# NANO100BN_v1 register map
File version: 1.0
Registers are 32-bit, read-write, reset 0x0 unless marked. A register's access mark holds for its fields unless they carry their own. Offsets are from the block's base; [hi:lo] are bit positions; {n}, {i} and the like mark numbered series; 'fields as' and 'values as' point back to an identical list.

## PWM0 — PWM Register Map
Base 0x40040000
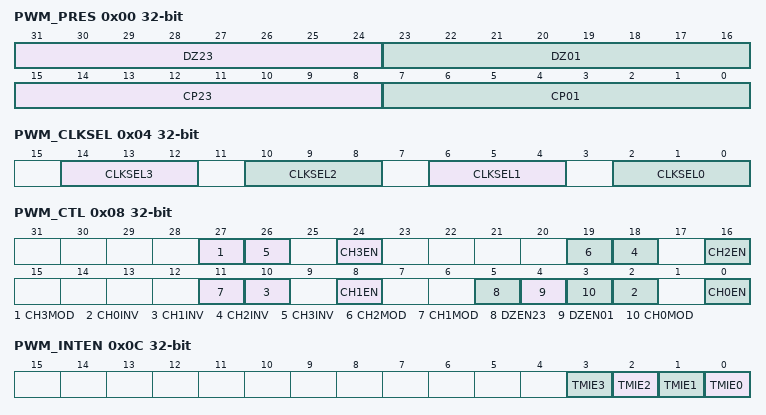
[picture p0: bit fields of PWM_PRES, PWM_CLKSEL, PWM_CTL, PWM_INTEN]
0x00 PWM_PRES — PWM Prescaler Register
  [31:24] DZ23 — Dead Zone Interval Register for CH2 and CH3 Pair. These 8 bits determine dead zone length. The unit time of dead zone length is received from clock selector 2.
  [23:16] DZ01 — Dead Zone Interval Register for CH0 and CH1 Pair. These 8 bits determine dead zone length. The unit time of dead zone length is received from clock selector 0.
  [15:8] CP23 — Clock Prescaler 2 for PWM Timer 2 3. Clock input is divided by (CP23 + 1) before it is fed to the counter 2 3
  [7:0] CP01 — Clock Prescaler 0 for PWM Timer 0 1. Clock input is divided by (CP01 + 1) before it is fed to the counter 0 1
0x04 PWM_CLKSEL — PWM Clock Select Register
  [14:12] CLKSEL3 — Timer 3 Clock Source Selection
  [10:8] CLKSEL2 — Timer 2Clock Source Selection. Select clock input for timer 2. (Table is the same as CLKSEL3)
  [6:4] CLKSEL1 — Timer 1 Clock Source Selection. Select clock input for timer 1. (Table is the same as CLKSEL3)
  [2:0] CLKSEL0 — Timer 0 Clock Source Selection. Select clock input for timer 0. (Table is the same as CLKSEL3)
0x08 PWM_CTL — PWM Control Register
  [27] CH3MOD — PWM-Timer 3 Continuous/One-shot Mode. Note: If there is a rising transition at this bit, it will cause CN and CM of PWM0_DUTY3 to be cleared.
    0=One-Shot Mode; 1=Continuous Mode
  [8n+2] CH{n}INV (n=0..3) — PWM-Timer {n} Output Inverter ON/OFF
    0=Inverter OFF; 1=Inverter ON
  [8n] CH{n}EN (n=0..3) — PWM-Timer {n} Enable/Disable Start Run
    0=PWM-Timer {n} Running Stopped; 1=PWM-Timer {n} Start Run Enabled
  [19] CH2MOD — PWM-Timer 2 Continuous/One-shot Mode. Note: If there is a rising transition at this bit, it will cause CN and CM of PWM0_DUTY2 be cleared.
    0=One-Shot Mode; 1=Continuous Mode
  [11] CH1MOD — PWM-Timer 1 Continuous/One-shot Mode. Note: If there is a rising transition at this bit, it will cause CN and CM of PWM0_DUTY1 to be cleared.
    0=One-Shot Mode; 1=Continuous Mode
  [5] DZEN23 — Dead-Zone 2 Generator Enable/Disable. Note: When Dead-Zone Generator is enabled, the pair of PWM2 and PWM3 becomes a complementary pair.
    0=Disabled; 1=Enabled
  [4] DZEN01 — Dead-Zone 0 Generator Enable/Disable. Note: When Dead-Zone Generator is enabled, the pair of PWM0 and PWM1 becomes a complementary pair.
    0=Disabled; 1=Enabled
  [3] CH0MOD — PWM-Timer 0 Continuous/One-Shot Mode. Note: If there is a rising transition at this bit, it will cause CN and CM of PWM0_DUTY0 to be cleared.
    0=One-Shot Mode; 1=Continuous Mode
0x0C PWM_INTEN — PWM Interrupt Enable Register
  [all] fields
    0=Disabled; 1=Enabled
  [n] TMIE{n} (n=0..3) — PWM Timer {n} Interrupt Enable
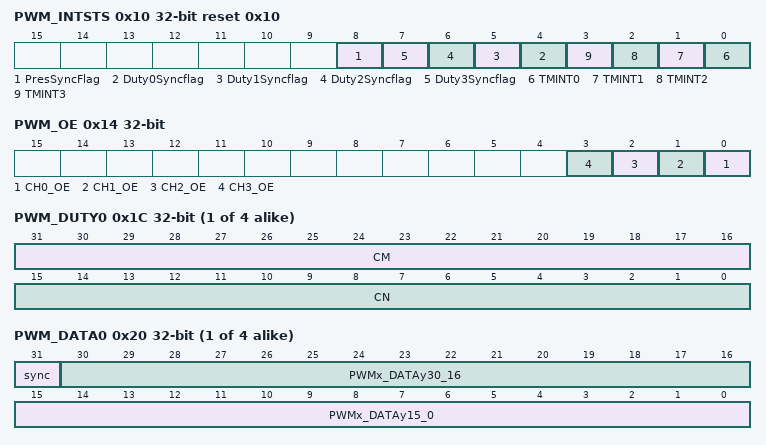
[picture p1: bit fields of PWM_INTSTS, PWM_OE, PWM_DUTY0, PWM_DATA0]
0x10 PWM_INTSTS reset 0x10 — PWM Interrupt Indication Register
  [8] PresSyncFlag — Prescale Synchronize Flag. Note: software should check this flag when writing Prescale, if this flag is set, and user ignore this flag and change Prescale, the Prescale may be wrong for one prescale cycle
    0=Prescale has been synchronized to ECLK domain; 1=Prescale is synchronizing to ECLK domain
  [n+4] Duty{n}Syncflag (n=0..3) — Duty{n} Synchronize Flag. Note: software should check this flag when writing duty{n}, if this flag is set, and user ignore this flag and change duty{n}, the corresponding CNR and CMR may be wrong for one duty cycle
    0=Duty{n} has been synchronized to ECLK domain; 1=Duty{n} is synchronizing to ECLK domain
  [n] TMINT{n} (n=0..3) — PWM Timer {n} Interrupt Flag. Flag is set by hardware when PWM{n} down counter reaches zero, software can clear this bit by writing a one to it.
0x14 PWM_OE — PWM Output Enable for PWM0~PWM3
  [n] CH{n}_OE (n=0..3) — PWM CH{n} Output Enable Register. Note: The corresponding GPI/O pin also must be switched to PWM function (refer to GPx_MFP)
    0=PWM CH{n} output to pin Disabled; 1=PWM CH{n} output to pin Enabled
{0x1C+0xC*i} PWM_DUTY{i} (i=0..3) — PWM Counter/Comparator Register {i}
  [31:16] CM — PWM Comparator Register. CM determines the PWM duty. Note: Any write to CM will take effect in next PWM cycle.
  [15:0] CN — PWM Counter/Timer Loaded Value. CN determines the PWM period. Note: Any write to CN will take effect in next PWM cycle.
{0x20+0xC*i} PWM_DATA{i} ro (i=0..3) — PWM Data Register {i}
  [31] sync — Indicate that CNR value is sync to PWM counter. Note: when the corresponding cascade enable .bit is set is bit will not appear in the corresponding channel
    0=CNR value is sync to PWM counter; 1=CNR value is not sync to PWM counter
  [30:16] PWMx_DATAy30_16 — PWM Data Register. User can monitor PWMx_DATAy to know the current value in 32-bit down count counter. Notes:This will be valid only for the corresponding cascade enable .bit is set
  [15:0] PWMx_DATAy15_0 — PWM Data Register. User can monitor PWMx_DATAy to know the current value in 16-bit down count counter.
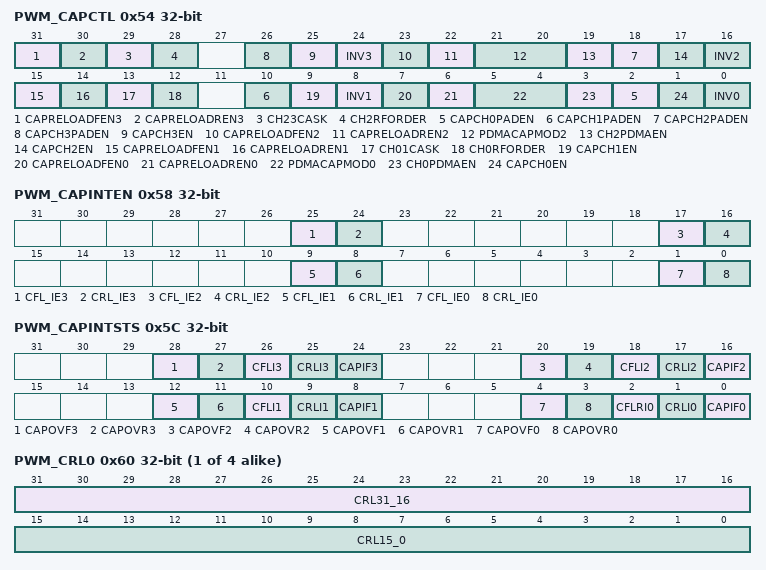
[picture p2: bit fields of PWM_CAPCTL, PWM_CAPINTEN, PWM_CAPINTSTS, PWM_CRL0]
0x54 PWM_CAPCTL — Capture Control Register
  [31] CAPRELOADFEN3 — Reload CNR3 when CH3 falling capture Event Comes
    0=Falling capture reload for CH3 Disabled; 1=Falling capture reload for CH3 Enabled
  [30] CAPRELOADREN3 — Reload CNR3 when CH3 Rising Capture Event Comes
    0=Rising capture reload for CH3 Disabled; 1=Rising capture reload for CH3 Enabled
  [29] CH23CASK — Cascade channel 2 and channel 3 PWM counter for capturing usage
  [28] CH2RFORDER
    0=PWM_CFL2 is the first captured data to memory; 1=PWM_CRL2 is the first captured data to memory
  [8n+2] CAPCH{n}PADEN (n=0..3) — Capture Input Enable Register
    0=OFF; 1=ON
  [25] CAPCH3EN — Capture Channel 3 transition Enable/Disable. When Enabled, Capture latched the PMW-timer and saved to PWM_CRL3 (Rising latch) and PWM_CFL3 (Falling latch). When Disabled, Capture does not update PWM_CRL3 and PWM_CFL3, and disable Channel 3 Interrupt.
    0=Capture function on channel 3 Disabled; 1=Capture function on channel 3 Enabled
  [8n] INV{n} (n=0..3) — Channel {n} Inverter ON/OFF
    0=Inverter OFF; 1=Inverter ON. Reverse the input signal from GPIO before fed to Capture timer
  [23] CAPRELOADFEN2 — Reload CNR2 when CH2 capture failing event coming
    0=Failing capture reload for CH2 Disabled; 1=Failing capture reload for CH2 Enabled
  [22] CAPRELOADREN2 — Reload CNR2 when CH2 capture rising event coming
    0=Rising capture reload for CH2 Disabled; 1=Rising capture reload for CH2 Enabled
  [21:20] PDMACAPMOD2 — Select CRL2 or CFL2 for PDMA Transfer
  [19] CH2PDMAEN — Channel 2 PDMA Enable
    0=Channel 2 PDMA function Disabled; 1=Channel 2 PDMA function Enabled for the channel 2 captured data and transfer to memory
  [17] CAPCH2EN — Capture Channel 2 transition Enable/Disable. When Enabled, Capture latched the PWM-timer value and saved to PWM_CRL2 (Rising latch) and PWM_CFL2 (Falling latch). When Disabled, Capture does not update PWM_CRL2 and PWM_CFL2, and disable Channel 2 Interrupt.
    0=Capture function on channel 2 Disabled; 1=Capture function on channel 2 Enabled
  [15] CAPRELOADFEN1 — Reload CNR1 when CH1 capture falling event coming
    0=Capture falling reload for CH1 Disabled; 1=Capture falling reload for CH1 Enabled
  [14] CAPRELOADREN1 — Reload CNR1 when CH1 Capture Rising Event Comes
    0=Rising capture reload for CH1 Disabled; 1=Rising capture reload for CH1 Enabled
  [13] CH01CASK — Cascade channel 0 and channel 1 PWM timer for capturing usage
  [12] CH0RFORDER
    0=PWM_CFL0 is the first captured data to memory; 1=PWM_CRL0 is the first captured data to memory
  [9] CAPCH1EN — Capture Channel 1 transition Enable/Disable. When Enabled, Capture latched the PMW-counter and saved to PWM_CRL1 (Rising latch) and PWM_CFL1 (Falling latch). When Disabled, Capture does not update PWM_CRL1 and PWM_CFL1, and disable Channel 1 Interrupt.
    0=Capture function on channel 1 Disabled; 1=Capture function on channel 1 Enabled
  [7] CAPRELOADFEN0 — Reload CNR0 when CH0 Capture Falling Event Comes
    0=Falling capture reload for CH0 Disabled; 1=Falling capture reload for CH0 Enabled
  [6] CAPRELOADREN0 — Reload CNR0 when CH0 Capture Rising Event Comes
    0=Rising capture reload for CH0 Disabled; 1=Rising capture reload for CH0 Enabled
  [5:4] PDMACAPMOD0 — Select CRL0 or CFL0 for PDMA Transfer
  [3] CH0PDMAEN — Channel 0 PDMA Enable
    0=Channel 0 PDMA function Disabled; 1=Channel 0 PDMA function Enabled for the channel 0 captured data and transfer to memory
  [1] CAPCH0EN — Capture Channel 0 transition Enable/Disable. When Enabled, Capture latched the PWM-timer value and saved to PWM_CRL0 (Rising latch) and PWM_CFL0 (Falling latch). When Disabled, Capture does not update PWM_CRL0 and PWM_CFL0, and disable Channel 0 Interrupt.
    0=Capture function on channel 0 Disabled; 1=Capture function on channel 0 Enabled
0x58 PWM_CAPINTEN — Capture interrupt enable Register
  [25] CFL_IE3 — Channel 3 Falling Latch Interrupt Enable ON/OFF. When Enabled, if Capture detects Channel 3 has falling transition, Capture issues an Interrupt.
    0=Falling latch interrupt Disabled; 1=Falling latch interrupt Enabled
  [24] CRL_IE3 — Channel 3 Rising Latch Interrupt Enable ON/OFF. When Enabled, if Capture detects Channel 3 has rising transition, Capture issues an Interrupt.
    0=Rising latch interrupt Disabled; 1=Rising latch interrupt Enabled
  [17] CFL_IE2 — Channel 2 Falling Latch Interrupt Enable ON/OFF. When Enabled, if Capture detects Channel 2 has falling transition, Capture issues an Interrupt.
    values as CFL_IE3
  [16] CRL_IE2 — Channel 2 Rising Latch Interrupt Enable ON/OFF. When Enabled, if Capture detects Channel 2 has rising transition, Capture issues an Interrupt.
    values as CRL_IE3
  [9] CFL_IE1 — Channel 1 Falling Latch Interrupt Enable. When Enabled, if Capture detects Channel 1 has falling transition, Capture issues an Interrupt.
    values as CFL_IE3
  [8] CRL_IE1 — Channel 1 Rising Latch Interrupt Enable. When Enabled, if Capture detects Channel 1 has rising transition, Capture issues an Interrupt.
    values as CRL_IE3
  [1] CFL_IE0 — Channel 0 Falling Latch Interrupt Enable ON/OFF. When Enabled, if Capture detects Channel 0 has falling transition, Capture issues an Interrupt.
    values as CFL_IE3
  [0] CRL_IE0 — Channel 0 Rising Latch Interrupt Enable ON/OFF. When Enabled, if Capture detects Channel 0 has rising transition, Capture issues an Interrupt.
    values as CRL_IE3
0x5C PWM_CAPINTSTS — Capture Interrupt Indication Register
  [28] CAPOVF3 — Capture Falling Flag Over Run for Channel 3. This flag indicate CFL3 update faster than software reading it when it is set. This bit will be cleared automatically when user clear CFLI3 bit 26 of PWM_CAPINTSTS
  [27] CAPOVR3 — Capture Rising Flag Over Run for Channel 3. This flag indicate CRL3update faster than software reading it when it is set. This bit will be cleared automatically when user clear CRLI3 bit 25 of PWM_CAPINTSTS
  [26] CFLI3 — PWM_CFL3 Latched Indicator Bit. When input channel 3 has a falling transition, PWM_CFL3 was latched with the value of PWM down-counter and this bit is set by hardware, software can clear this bit by writing 1 to it.
  [25] CRLI3 — PWM_CRL3 Latched Indicator Bit. When input channel 3 has a rising transition, PWM_CRL3 was latched with the value of PWM down-counter and this bit is set by hardware, software can clear this bit by writing 1 to it.
  [8n] CAPIF{n} (n=0..3) — Capture{n} Interrupt Indication Flag
  [20] CAPOVF2 — Capture Falling Flag Over Run for Channel 2. This flag indicate CFL2 update faster than software reading it when it is set. This bit will be cleared automatically when user clear CFLI2 bit 18 of PWM_CAPINTSTS
  [19] CAPOVR2 — Capture Rising Flag Over Run for Channel 2. This flag indicate CRL2 update faster than software reading it when it is set. This bit will be cleared automatically when user clear CRLI2 bit 17 of PWM_CAPINTSTS
  [18] CFLI2 — PWM_CFL2 Latched Indicator Bit. When input channel 2 has a falling transition, PWM0_CFL2 was latched with the value of PWM down-counter and this bit is set by hardware, software can clear this bit by writing 1 to it.
  [17] CRLI2 — PWM_CRL2 Latched Indicator Bit. When input channel 2 has a rising transition, PWM0_CRL2 was latched with the value of PWM down-counter and this bit is set by hardware, software can clear this bit by writing 1 to it.
  [12] CAPOVF1 — Capture Falling Flag Over Run for Channel 1. This flag indicate CFL1 update faster than software reading it when it is set. This bit will be cleared automatically when user clear CFLI1 bit 10 of PWM_CAPINTSTS
  [11] CAPOVR1 — Capture Rising Flag Over Run for Channel 1. This flag indicate CRL1 update faster than software reading it when it is set. This bit will be cleared automatically when user clear CRLI1 bit 9 of PWM_CAPINTSTS
  [10] CFLI1 — PWM_CFL1 Latched Indicator Bit. When input channel 1 has a falling transition, PWM0_CFL1 was latched with the value of PWM down-counter and this bit is set by hardware, software can clear this bit by writing 1 to it.
  [9] CRLI1 — PWM_CRL1 Latched Indicator Bit. When input channel 1 has a rising transition, PWM0_CRL1 was latched with the value of PWM down-counter and this bit is set by hardware, software can clear this bit by writing 1 to it.
  [4] CAPOVF0 — Capture Falling Flag Over Run for Channel 0. This flag indicate CFL0 update faster than software reading it when it is set.
  [3] CAPOVR0 — Capture Rising Flag Over Run for Channel 0. This flag indicate CRL0 update faster than software reading it when it is set. This bit will be cleared automatically when user clears CRLI0 bit 1 of PWM_CAPINTSTS.
  [2] CFLRI0 — PWM_CFL0 Latched Indicator Bit. When input channel 0 has a falling transition, PWM0_CFL0 was latched with the value of PWM down-counter and this bit is set by hardware, software can clear this bit by writing 1 to it.
  [1] CRLI0 — PWM_CRL0 Latched Indicator Bit. When input channel 0 has a rising transition, PWM0_CRL0 was latched with the value of PWM down-counter and this bit is set by hardware, software can clear this bit by writing 1 to it.
{0x60+8i} PWM_CRL{i} ro (i=0..3) — Capture Rising Latch Register (Channel {i})
  [31:16] CRL31_16 — Upper Half Word of 32-bit Capture Data when Cascade Enabled. When cascade is enabled for capture channel 0, 2,the original 16 bit counter extend to 32 bit, and capture result CRL0 and CRL2 are also extend to 32 bit,
  [15:0] CRL15_0 — Capture Rising Latch Register. Latch the PWM counter when Channel 0/1/2/3 has rising transition.
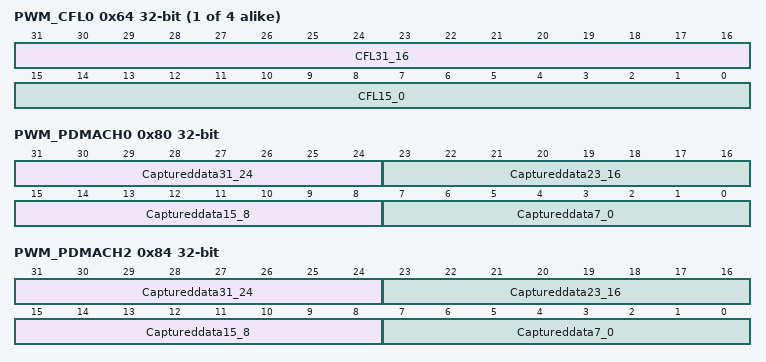
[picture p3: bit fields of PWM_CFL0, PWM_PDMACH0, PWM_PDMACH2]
{0x64+8i} PWM_CFL{i} ro (i=0..3) — Capture Falling Latch Register (Channel {i})
  [31:16] CFL31_16 — Upper Half Word of 32-bit Capture Data When Cascade Enabled. When cascade is enabled for capture channel 0, 2, the original 16 bit counter extend to 32 bit, and capture result CFL0 and CFL2 are also extend to 32 bit,
  [15:0] CFL15_0 — Capture Falling Latch Register. Latch the PWM counter when Channel 01/2/3 has Falling transition.
0x80 PWM_PDMACH0 ro — PDMA channel 0 captured data
  [31:24] Captureddata31_24 — PDMACH0. When CH01CASK is disabled, this byte is 0. When CH01CASK is enabled, It is the 4th byte of 32 bit capturing data for channel 0
  [23:16] Captureddata23_16 — PDMACH0. When CH01CASK is disabled, this byte is 0. When CH01CASK is enabled, It is the third byte of 32 bit capturing data for channel 0
  [15:8] Captureddata15_8 — PDMACH0. When CH01CASK is disabled, it is the capturing value(CFL0/CRL0) for channel 0. When CH01CASK is enabled, It is the second byte of 32 bit capturing data for channel 0
  [7:0] Captureddata7_0 — PDMACH0. When CH01CASK is disabled, it is the capturing value(CFL0/CRL0) for channel 0. When CH01CASK is enabled, It is the for the first byte of 32 bit capturing data for channel 0
0x84 PWM_PDMACH2 ro — PDMA channel 2 captured data
  [31:24] Captureddata31_24 — PDMACH0. When CH23CASK is disabled, this byte is 0. When CH23CASK is enabled, It is the 4th byte of 32 bit capturing data for channel 2
  [23:16] Captureddata23_16 — PDMACH0. When CH23CASK is disabled, this byte is 0. When CH23CASK is enabled, It is the third byte of 32 bit capturing data for channel 2
  [15:8] Captureddata15_8 — PDMACH0. When CH23CASK is disabled, it is the capturing value(CFL0/CRL0) for channel 2. When CH23CASK is enabled, It is the second byte of 32 bit capturing data for channel 2
  [7:0] Captureddata7_0 — PDMACH0. When CH23CASK is disabled, it is the capturing value(CFL0/CRL0) for channel 2. When CH23CASK is enabled, It is the for the first byte of 32 bit capturing data for channel 2

## PWM1 — PWM Register Map
Base 0x40140000
Registers as PWM0; these are added or differ:
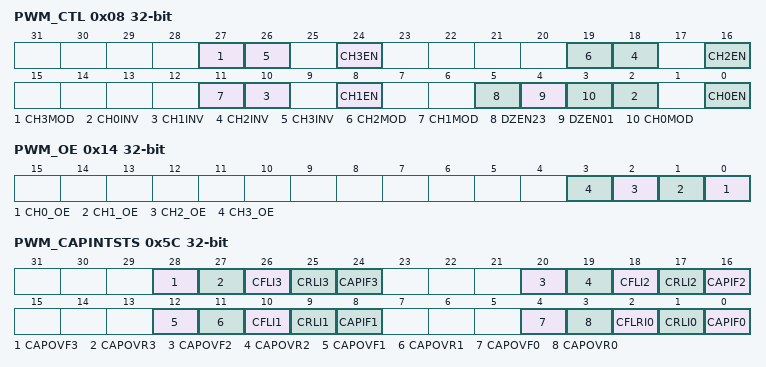
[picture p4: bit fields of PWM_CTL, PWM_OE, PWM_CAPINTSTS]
0x08 PWM_CTL — PWM Control Register
  fields as PWM0.PWM_CTL
0x14 PWM_OE — PWM Output Enable for PWM0~PWM3
  fields as PWM0.PWM_OE
0x5C PWM_CAPINTSTS — Capture Interrupt Indication Register
  fields as PWM0.PWM_CAPINTSTS
